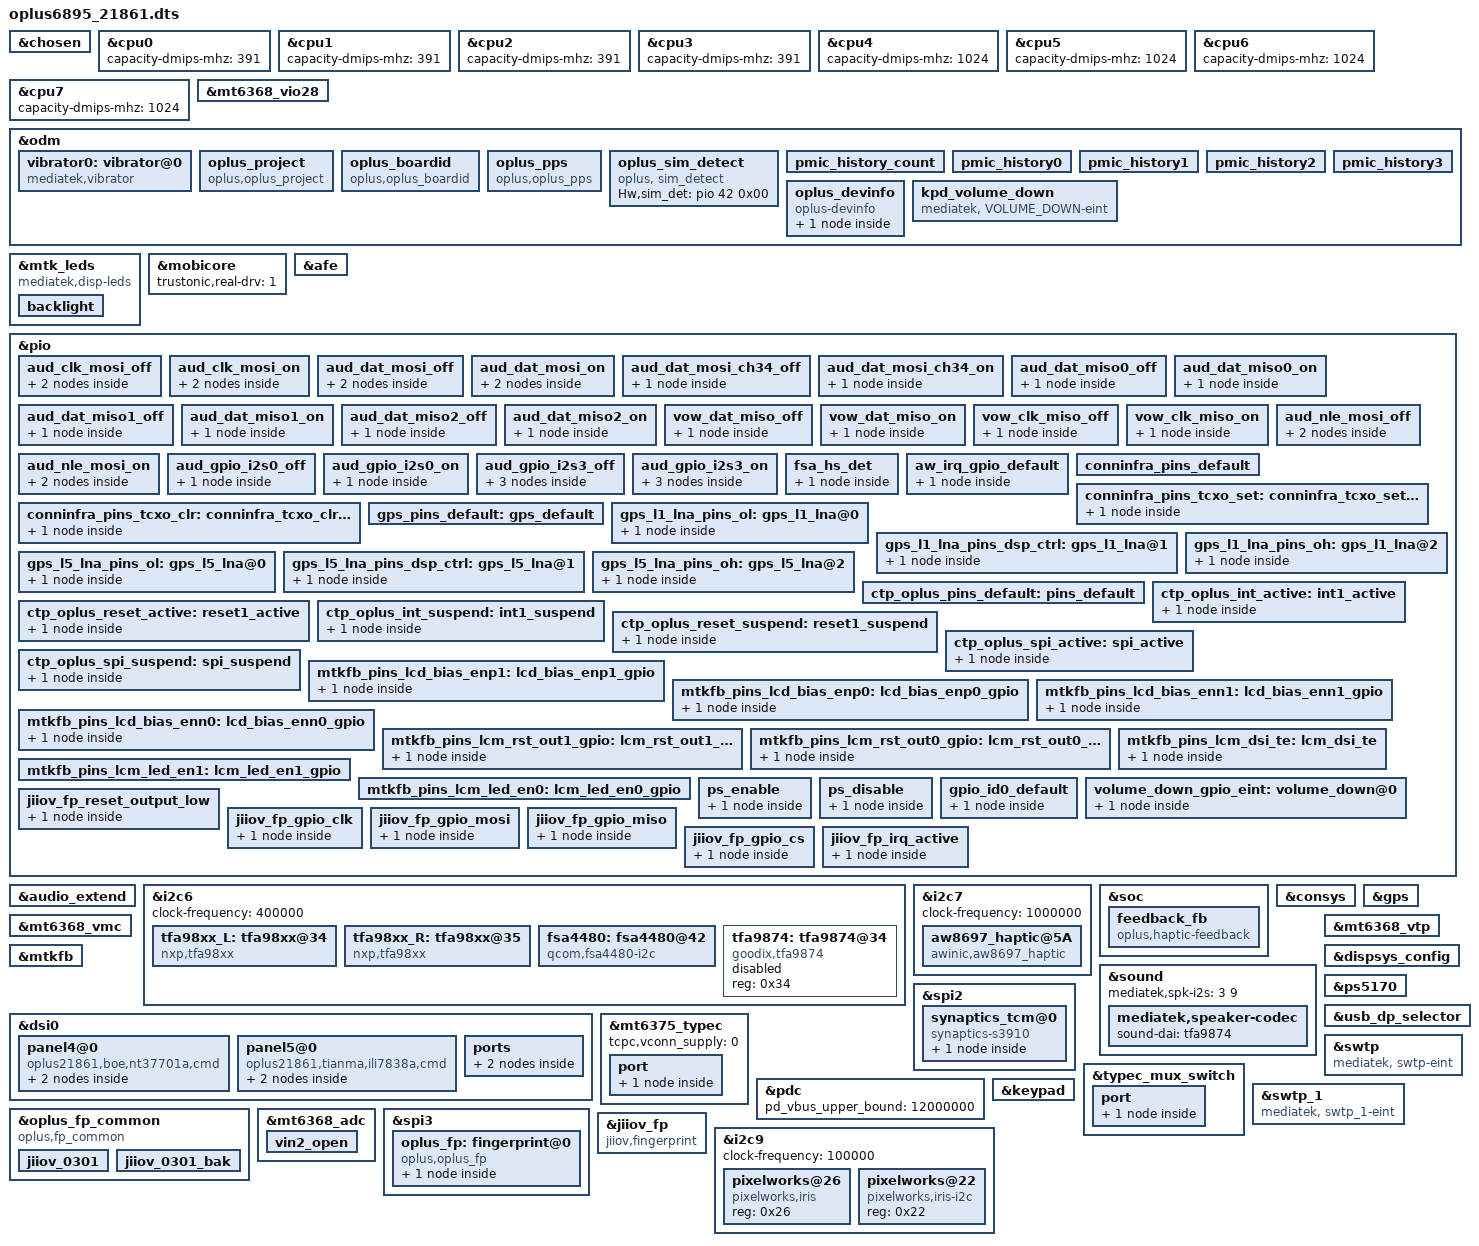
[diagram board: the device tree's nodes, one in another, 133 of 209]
// SPDX-License-Identifier: (GPL-2.0 OR MIT)
/*
 * Copyright (C) 2020 MediaTek Inc.
 * Author: Chun-Hung Wu <chun-hung.wu@mediatek.com>
 */
/dts-v1/;
/plugin/;
#include <dt-bindings/interrupt-controller/arm-gic.h>
#include <dt-bindings/interrupt-controller/irq.h>
#include <dt-bindings/phy/phy.h>
#include <dt-bindings/pinctrl/mt6895-pinfunc.h>
#include "mediatek/oplus_charge_21861.dtsi"
#include <dt-bindings/iio/mt635x-auxadc.h>

//#ifdef OPLUS_FEATURE_NFC_BRINGUP
#include "mediatek/nfc/mt6895_pickle_21861_sn100.dtsi"
//#endif OPLUS_FEATURE_NFC_BRINGUP

//#ifdef OPLUS_FEATURE_SENSOR
#include "mediatek/oplus_sensor_21861.dtsi"
//#endif

&chosen {
	bootargs_ext = "console=tty0 root=/dev/ram \
loglevel=8 \
androidboot.hardware=mt6895 \
initcall_debug=1 ";
};

&cpu0 {
        capacity-dmips-mhz = <391>;
};

&cpu1 {
        capacity-dmips-mhz = <391>;
};

&cpu2 {
        capacity-dmips-mhz = <391>;
};

&cpu3 {
        capacity-dmips-mhz = <391>;
};

&cpu4 {
        capacity-dmips-mhz = <1024>;
};

&cpu5 {
        capacity-dmips-mhz = <1024>;
};

&cpu6 {
        capacity-dmips-mhz = <1024>;
};

&cpu7 {
        capacity-dmips-mhz = <1024>;
};


&mt6368_vio28 {
       regulator-min-microvolt = <3000000>;
       regulator-max-microvolt = <3000000>;
};

&odm {
	vibrator0:vibrator@0 {
		compatible = "mediatek,vibrator";
		vib_timer = <25>;
		vib_limit = <9>;
		vib_vol= <9>;
	};
};

&mtk_leds {
	compatible = "mediatek,disp-leds";
	backlight {
		label = "lcd-backlight";
		led_mode = <4>;
		max-brightness = <10239>;
		max-hw-brightness = <10239>;
		led-bits = <13>;
	};
};

/*Trustonic Mobicore real driver*/
&mobicore {
	trustonic,real-drv=<1>;
};

/* AUDIO GPIO standardization start */
&afe {
	pinctrl-names = "aud_clk_mosi_off",
			"aud_clk_mosi_on",
			"aud_dat_mosi_off",
			"aud_dat_mosi_on",
			"aud_dat_mosi_ch34_off",
			"aud_dat_mosi_ch34_on",
			"aud_dat_miso0_off",
			"aud_dat_miso0_on",
			"aud_dat_miso1_off",
			"aud_dat_miso1_on",
			"aud_dat_miso2_off",
			"aud_dat_miso2_on",
			"vow_dat_miso_off",
			"vow_dat_miso_on",
			"vow_clk_miso_off",
			"vow_clk_miso_on",
			"aud_gpio_i2s3_off",
			"aud_gpio_i2s3_on",
			"aud_gpio_i2s0_off",
			"aud_gpio_i2s0_on";
	pinctrl-0 = <&aud_clk_mosi_off>;
	pinctrl-1 = <&aud_clk_mosi_on>;
	pinctrl-2 = <&aud_dat_mosi_off>;
	pinctrl-3 = <&aud_dat_mosi_on>;
	pinctrl-4 = <&aud_dat_mosi_ch34_off>;
	pinctrl-5 = <&aud_dat_mosi_ch34_on>;
	pinctrl-6 = <&aud_dat_miso0_off>;
	pinctrl-7 = <&aud_dat_miso0_on>;
	pinctrl-8 = <&aud_dat_miso1_off>;
	pinctrl-9 = <&aud_dat_miso1_on>;
	pinctrl-10 = <&aud_dat_miso2_off>;
	pinctrl-11 = <&aud_dat_miso2_on>;
	pinctrl-12 = <&vow_dat_miso_off>;
	pinctrl-13 = <&vow_dat_miso_on>;
	pinctrl-14 = <&vow_clk_miso_off>;
	pinctrl-15 = <&vow_clk_miso_on>;
	pinctrl-16 = <&aud_gpio_i2s3_off>;
	pinctrl-17 = <&aud_gpio_i2s3_on>;
	pinctrl-18 = <&aud_gpio_i2s0_off>;
	pinctrl-19 = <&aud_gpio_i2s0_on>;
};
&pio {
	aud_clk_mosi_off: aud_clk_mosi_off {
		pins_cmd1_dat {
			pinmux = <PINMUX_GPIO202__FUNC_GPIO202>;
			input-enable;
			bias-pull-down;
		};
		pins_cmd2_dat {
			pinmux = <PINMUX_GPIO203__FUNC_GPIO203>;
			input-enable;
			bias-pull-down;
		};
	};
	aud_clk_mosi_on: aud_clk_mosi_on {
		pins_cmd1_dat {
			pinmux = <PINMUX_GPIO202__FUNC_AUD_CLK_MOSI>;
			input-schmitt-enable;
			bias-disable;
		};
		pins_cmd2_dat {
			pinmux = <PINMUX_GPIO203__FUNC_AUD_SYNC_MOSI>;
			input-schmitt-enable;
			bias-disable;
		};
};
	aud_dat_mosi_off: aud_dat_mosi_off {
		pins_cmd1_dat {
			pinmux = <PINMUX_GPIO204__FUNC_GPIO204>;
			input-enable;
			bias-pull-down;
		};
		pins_cmd2_dat {
			pinmux = <PINMUX_GPIO205__FUNC_GPIO205>;
			input-enable;
			bias-pull-down;
		};
};
	aud_dat_mosi_on: aud_dat_mosi_on {
		pins_cmd1_dat {
			pinmux = <PINMUX_GPIO204__FUNC_AUD_DAT_MOSI0>;
			input-schmitt-enable;
			bias-disable;
		};
		pins_cmd2_dat {
			pinmux = <PINMUX_GPIO205__FUNC_AUD_DAT_MOSI1>;
			input-schmitt-enable;
			bias-disable;
		};
};
	aud_dat_mosi_ch34_off: aud_dat_mosi_ch34_off {
		pins_cmd1_dat {
			pinmux = <PINMUX_GPIO206__FUNC_GPIO206>;
			input-enable;
			bias-pull-down;
		};
	};
	aud_dat_mosi_ch34_on: aud_dat_mosi_ch34_on {
		pins_cmd1_dat {
			pinmux = <PINMUX_GPIO206__FUNC_AUD_DAT_MOSI2>;
			input-schmitt-enable;
			bias-disable;
		};
	};
	aud_dat_miso0_off: aud_dat_miso0_off {
		pins_cmd1_dat {
			pinmux = <PINMUX_GPIO209__FUNC_GPIO209>;
			input-enable;
			bias-pull-down;
		};
	};
	aud_dat_miso0_on: aud_dat_miso0_on {
		pins_cmd1_dat {
			pinmux = <PINMUX_GPIO209__FUNC_AUD_DAT_MISO0>;
			input-schmitt-enable;
			bias-disable;
		};
	};
	aud_dat_miso1_off: aud_dat_miso1_off {
		pins_cmd1_dat {
			pinmux = <PINMUX_GPIO210__FUNC_GPIO210>;
			input-enable;
			bias-disable;
		};
	};
	aud_dat_miso1_on: aud_dat_miso1_on {
		pins_cmd1_dat {
			pinmux = <PINMUX_GPIO210__FUNC_AUD_DAT_MISO1>;
			input-schmitt-enable;
			bias-disable;
		};
	};
	aud_dat_miso2_off: aud_dat_miso2_off {
		pins_cmd1_dat {
			pinmux = <PINMUX_GPIO211__FUNC_GPIO211>;
			input-enable;
			bias-pull-down;
		};
	};
	aud_dat_miso2_on: aud_dat_miso2_on {
		pins_cmd1_dat {
			pinmux = <PINMUX_GPIO211__FUNC_AUD_DAT_MISO2>;
			input-schmitt-enable;
			bias-disable;
		};
	};
	vow_dat_miso_off: vow_dat_miso_off {
		pins_cmd1_dat {
			pinmux = <PINMUX_GPIO209__FUNC_GPIO209>;
			input-enable;
			bias-pull-down;
		};
	};
	vow_dat_miso_on: vow_dat_miso_on {
		pins_cmd1_dat {
			pinmux = <PINMUX_GPIO209__FUNC_VOW_DAT_MISO>;
			input-schmitt-enable;
			bias-disable;
		};
	};
	vow_clk_miso_off: vow_clk_miso_off {
		pins_cmd1_dat {
			pinmux = <PINMUX_GPIO210__FUNC_GPIO210>;
			input-enable;
			bias-pull-down;
		};
	};
	vow_clk_miso_on: vow_clk_miso_on {
		pins_cmd1_dat {
			pinmux = <PINMUX_GPIO210__FUNC_VOW_CLK_MISO>;
			input-schmitt-enable;
			bias-disable;
		};
	};
	aud_nle_mosi_off: aud_nle_mosi_off {
		pins_cmd1_dat {
			pinmux = <PINMUX_GPIO207__FUNC_GPIO207>;
			input-enable;
			bias-pull-down;
		};
		pins_cmd2_dat {
			pinmux = <PINMUX_GPIO208__FUNC_GPIO208>;
			input-enable;
			bias-pull-down;
		};
	};
	aud_nle_mosi_on: aud_nle_mosi_on {
		pins_cmd1_dat {
			pinmux = <PINMUX_GPIO207__FUNC_AUD_NLE_MOSI1>;
			input-schmitt-enable;
			bias-disable;
		};
		pins_cmd2_dat {
			pinmux = <PINMUX_GPIO208__FUNC_AUD_NLE_MOSI0>;
			input-schmitt-enable;
			bias-disable;
		};
	};
	aud_gpio_i2s0_off: aud_gpio_i2s0_off {
		pins_cmd1_dat {
			pinmux = <PINMUX_GPIO117__FUNC_GPIO117>;
			input-enable;
			bias-pull-down;
		};
	};
	aud_gpio_i2s0_on: aud_gpio_i2s0_on {
		pins_cmd1_dat {
			pinmux = <PINMUX_GPIO117__FUNC_I2S0_DI>;
			input-schmitt-enable;
			bias-disable;
		};
	};
	aud_gpio_i2s3_off: aud_gpio_i2s3_off {
		pins_cmd1_dat {
			pinmux = <PINMUX_GPIO115__FUNC_GPIO115>;
			input-enable;
			bias-pull-down;
		};
		pins_cmd2_dat {
			pinmux = <PINMUX_GPIO116__FUNC_GPIO116>;
			input-enable;
			bias-pull-down;
		};
		pins_cmd3_dat {
			pinmux = <PINMUX_GPIO118__FUNC_GPIO118>;
			input-enable;
			bias-pull-down;
		};
	};
	aud_gpio_i2s3_on: aud_gpio_i2s3_on {
		pins_cmd1_dat {
			pinmux = <PINMUX_GPIO115__FUNC_I2S3_BCK>;
			input-schmitt-enable;
			bias-disable;
		};
		pins_cmd2_dat {
			pinmux = <PINMUX_GPIO116__FUNC_I2S3_LRCK>;
			input-schmitt-enable;
			bias-disable;
		};
		pins_cmd3_dat {
			pinmux = <PINMUX_GPIO118__FUNC_I2S3_DO>;
			input-schmitt-enable;
			bias-disable;
		};
	};
};
/* AUDIO GPIO standardization end */

//#ifdef OPLUS_ARCH_EXTENDS
&audio_extend {
	//for nxp speaker
	oplus,speaker-vendor = "nxp";
	oplus,speaker-i2s-id = <3>;
	oplus,speaker-i2s-id-in = <0>;
	oplus,speaker-codec-name = "tfa98xx.6-0034","tfa98xx.6-0035";
	oplus,speaker-codec-dai-name = "tfa98xx-aif-6-34","tfa98xx-aif-6-35";
};

&i2c6 {
	clock-frequency = <400000>;

	tfa98xx_L: tfa98xx@34 {
		compatible = "nxp,tfa98xx";
		reg = <0x34>;
		reset-gpio = <&pio 157 0>;
		tfa_min_range = <5000>;
		tfa_max_range = <8000>;
		tfa_channel = <0>;
		status = "okay";
	};

	tfa98xx_R: tfa98xx@35 {
		compatible = "nxp,tfa98xx";
		reg = <0x35>;
		reset-gpio = <&pio 158 0>;
		tfa_min_range = <5000>;
		tfa_max_range = <8000>;
		tfa_channel = <1>;
		status = "okay";
	};
};

&i2c6 {
	fsa4480: fsa4480@42 {
		compatible = "qcom,fsa4480-i2c";
		reg = <0x42>;
		pinctrl-names = "default";
		pinctrl-0 = <&fsa_hs_det>;
		fsa4480,hs-det-gpio = <&pio 53 0>;
	};
};

&i2c7 {
	status = "okay";
	clock-frequency = <1000000>;

	// AWINIC AW8697 Haptic
	aw8697_haptic@5A {
		status = "okay";
		compatible = "awinic,aw8697_haptic";
		reg = <0x5A>;
		reset-gpio = <&pio 24 0x00>;
		irq-gpio = <&pio 11 0x00>;
		qcom,device_id = <815>;

		pinctrl-names = "default";
		pinctrl-0 = <&aw_irq_gpio_default>;
	};
};

&soc {
	feedback_fb: feedback_fb {
		compatible = "oplus,haptic-feedback";
	};
};

&pio {
	fsa_hs_det: fsa_hs_det {
		pins_cmd_dat {
			pinmux = <PINMUX_GPIO53__FUNC_GPIO53>;
			slew-rate = <1>;  /*direction 0:in, 1:out*/
			output-high;
		};
	};

	aw_irq_gpio_default: aw_irq_gpio_default {
		pins_cmd_dat {
			pinmux = <PINMUX_GPIO11__FUNC_GPIO11>;
			input-enable;
			bias-pull-up;
		};
	};
};
//#endif /*OPLUS_ARCH_EXTENDS*/

&i2c6 {
	tfa9874: tfa9874@34 {
		compatible = "goodix,tfa9874";
		#sound-dai-cells = <0>;
		reg = <0x34>;
		status = "disabled";
	};
};

/*
&i2c6 {
	spk: speaker_amp@5c {
		compatible = "richtek,rt5512";
		#sound-dai-cells = <0>;
		reg = <0x5c>;
		status = "okay";
		sound-name-prefix = "Left";
	};
};
*/

/* CONNSYS TCXO GPIO start */
&consys {
	tcxo_support = "false";
	pinctrl-names = "default", "conninfra_tcxo_set", "conninfra_tcxo_clr";
	pinctrl-0 = <&conninfra_pins_default>;
	pinctrl-1 = <&conninfra_pins_tcxo_set>;
	pinctrl-2 = <&conninfra_pins_tcxo_clr>;
	status = "okay";
};

&pio {
	conninfra_pins_default: conninfra_pins_default {
	};
	conninfra_pins_tcxo_set: conninfra_tcxo_set@gpio {
		pins_cmd_dat {
			pinmux = <PINMUX_GPIO108__FUNC_CONN_TCXOENA_REQ>;
		};
	};
	conninfra_pins_tcxo_clr: conninfra_tcxo_clr@gpio {
		pins_cmd_dat {
			pinmux = <PINMUX_GPIO108__FUNC_GPIO108>;
		};
	};
};
/* CONNSYS TCXO GPIO end */

/* GPS GPIO standardization start */
&pio {
	gps_pins_default: gps_default {
	};

	gps_l1_lna_pins_ol: gps_l1_lna@0 {
		pins_cmd_dat {
			pinmux = <PINMUX_GPIO176__FUNC_GPIO176>;
			output-low;
		};
	};
	gps_l1_lna_pins_dsp_ctrl: gps_l1_lna@1 {
		pins_cmd_dat {
			pinmux = <PINMUX_GPIO176__FUNC_GPS_L1_ELNA_EN>;
		};
	};
	gps_l1_lna_pins_oh: gps_l1_lna@2 {
		pins_cmd_dat {
			pinmux = <PINMUX_GPIO176__FUNC_GPIO176>;
			output-high;
		};
	};

	gps_l5_lna_pins_ol: gps_l5_lna@0 {
		pins_cmd_dat {
			pinmux = <PINMUX_GPIO177__FUNC_GPIO177>;
			output-low;
		};
	};
	gps_l5_lna_pins_dsp_ctrl: gps_l5_lna@1 {
		pins_cmd_dat {
			pinmux = <PINMUX_GPIO177__FUNC_GPS_L5_ELNA_EN>;
		};
	};
	gps_l5_lna_pins_oh: gps_l5_lna@2 {
		pins_cmd_dat {
			pinmux = <PINMUX_GPIO177__FUNC_GPIO177>;
			output-high;
		};
	};
};

&gps {
	pinctrl-names = "default",
		"gps_l1_lna_disable",
		"gps_l1_lna_dsp_ctrl",
		"gps_l1_lna_enable",
		"gps_l5_lna_disable",
		"gps_l5_lna_dsp_ctrl",
		"gps_l5_lna_enable";
	pinctrl-0 = <&gps_pins_default>;
	pinctrl-1 = <&gps_l1_lna_pins_ol>;
	pinctrl-2 = <&gps_l1_lna_pins_dsp_ctrl>;
	pinctrl-3 = <&gps_l1_lna_pins_oh>;
	pinctrl-4 = <&gps_l5_lna_pins_ol>;
	pinctrl-5 = <&gps_l5_lna_pins_dsp_ctrl>;
	pinctrl-6 = <&gps_l5_lna_pins_oh>;
	status = "okay";
};
/* GPS GPIO standardization end */

&sound {
	mediatek,spk-i2s = <3 9>;
	mediatek,speaker-codec {
		sound-dai = <&tfa9874>;
	};
};

&spi2 {
	status = "okay";
	#address-cells = <1>;
	#size-cells = <0>;
	synaptics_tcm@0{
		compatible = "synaptics-s3910";
		reg = <0x0>;
		chip-name = "S3910";
		status = "okay";
		spi-max-frequency = <5000000>;
		/* Interrupt && Irq-gpio */
		interrupt-parent = <&pio>;
		interrupts = <135 0x2008>;

		/* Power Config */
		vdd_2v8-supply  = <&mt6368_vtp>;
		vdd_2v8_volt = <3000000>;
		vcc_1v8-supply  = <&mt6368_vmc>;
		vcc_1v8_volt = <1800000>;
		 
		/* Other HW Resource */

		irq-gpio = <&pio 135 0x2008>;
		reset-gpio = <&pio 212 0x1>;
		//cs-gpio = <&pio 110 0x00>;
		//pinctrl-names = "default";
		//pinctrl-0 = <&ts_int_active &ts_reset_active>;

		pinctrl-names = "default",  "oplus_int_active",
		"oplus_reset_active", "oplus_int_suspend",
		"oplus_reset_suspend", "oplus_spi_active",
		"oplus_spi_suspend";
		pinctrl-0 = <&ctp_oplus_pins_default>;
		pinctrl-1 = <&ctp_oplus_int_active>;
		pinctrl-2 = <&ctp_oplus_reset_active>;
		pinctrl-3 = <&ctp_oplus_int_suspend>;
		pinctrl-4 = <&ctp_oplus_reset_suspend>;
		pinctrl-5 = <&ctp_oplus_spi_active>;
		pinctrl-6 = <&ctp_oplus_spi_suspend>;

		touchpanel,max-num-support = <10>;
		touchpanel,tx-rx-num = <16 36>;
		earsense,tx-rx-num = <17 18>;
		touchpanel,panel-coords = <8640 19296>;
		touchpanel,display-coords = <1080 2412>;
		touchpanel,touchmajor-limit = <128 216>;
		touchpanel,elimination-range = <20 200 200>;
		touchpanel,int-mode = <1>; /*0: interrupt and disable, 1:interrupt and not disable*/
		touchpanel,smooth-level = <0 1 2 4 7 9>;
		touchpanel,smooth-level-charging = <0 2 4 7 8 9>;
		touchpanel,sensitive-level = <0 70 55 40 25 10>;
		touchpanel,single-optimized-time = <8>;
		touchpanel,high-frame-rate-time = <60>;

		vid_len = <2>;
		panel_type = <3 7>; /*type:3 BOE type:7 TIANMA*/
		platform_support_project = <21861 21862 21863 21641 21642 >;
		platform_support_project_dir = <21861 21861 21861 21641 21641 >;
		platform_support_project_commandline = "oplus21861_boe_nt37701a_fhd_dsi_cmd_lcm_drv","oplus21861_tianma_ili7838a_fhd_dsi_cmd_lcm_drv";

		prevention,curved_screen_V2;
		prevention,grip_disable_level = <6>;
		prevention,updelay_time_ms = <45>;
		prevention,makeup_cnt_weight = <5 1 2 2 2>;
		prevention,large_corner_range = <960 2400>;
		prevention,large_corner_judge_condition = <850 100 800 7 7>;
		prevention,trx_reject_condition = <8 7 7>;
		prevention,trx_strict_reject_condition = <8 6 6>;
		prevention,large_judge_time_ms = <500 50 30>;
		prevention,large_exit_condition = <8 8 2>;
		prevention,single_channel_width = <160 160>;
		prevention,normal_tap_condition = <10 350>;
		prevention,long_edge_condition = <240 150 180 80>;
		prevention,long_strict_edge_condition = <160 60>;
		prevention,long_fingerhold_condition = <100 6 4 4>;
		prevention,short_edge_condition = <200 90 180 80>;
		prevention,short_strict_edge_condition = <160 60>;
		prevention,large_strict_exit_condition = <6 6>;
		prevention,top_corner_config = <250 750 100>;
		prevention,edge_swipe_config = <150 500>;


		/* SW Support Feature Control */
		sportify_aod_gesture_support;
		black_gesture_support;
		pressure_report_support;
		charger_pump_support;
		game_switch_support;
		smart_gesture_support;
		spi_port_support;
		fw_update_app_support;
	    fingerprint_underscreen_support;
		freq_hop_simulate_support;
		report_flow_unlock_support;
		screenoff_fingerprint_info_support;
		irq_need_dev_resume_ok;
		enable_point_auto_change;
		report_rate_white_list_support;
		kernel_grip_support;
		//grip_no_driver_support;
		health_monitor_support;
		black_gesture_indep_support;
		algorithm_support;
		snr_read_support;
		exception_upload_support;
		/*
		 *Virtual Key Config:
		 *1:touchpanel,button-type: <virtualkey_type  supportted_button-map>
		 *virtualkey_type:
		 *Type 1: using board_properties
		 *Type 2: using same IC (button zone&& touch zone are seprate)
		 *Type 3: using diffrent IC (button zone&& touch zone are seprate)
		 *Type 4: No need of virtual key process
		 *supportted_button-map:select|menu|home|back
		 *
		 *2:touchpanel,button-map
		 *type (X1,Y1)(X2,Y2)(X3,Y3)(Width_X,Hight_Y)--Only when button-type is 0
		 */
		touchpanel,button-type = <4>;
		touchpanel.button-TRx = <0 0>;

		S3910 {
			switch_report_rate;
			report_rate_default = <60>;
			fps_report_rate = <60 2 90 3 120 3>;//1:360Hz 2:125Hz 3:240Hz
			fwupdate_bootloader = <1>;
			report_rate_game_value = <0x01>;
			default_gesture_mask = <8191>;
			normal_config_version = <0>; /* default config version has been changed to 2 in
				                       latest firmware and ic driver, old projects with
				                       old fw-cfg should config 0 in devicetrees */
		};
	};

};

&pio {
	ctp_oplus_pins_default: pins_default {
	};
	ctp_oplus_int_active: int1_active {
		pins_cmd_dat {
			pinmux = <PINMUX_GPIO135__FUNC_GPIO135>;
			bias-disable;
			input-enable;
		};
	};
	ctp_oplus_reset_active: reset1_active {
		pins_cmd_dat {
			pinmux = <PINMUX_GPIO212__FUNC_GPIO212>;
			output-high;
		};
	};
	ctp_oplus_int_suspend: int1_suspend {
		pins_cmd_dat {
			pinmux = <PINMUX_GPIO135__FUNC_GPIO135>;
			output-low;
		};
	};
	ctp_oplus_reset_suspend: reset1_suspend {
		pins_cmd_dat {
			pinmux = <PINMUX_GPIO212__FUNC_GPIO212>;
			output-low;
		};
	};
	ctp_oplus_spi_active: spi_active {
		pins_cmd_dat {
			pinmux = <PINMUX_GPIO109__FUNC_SPI2_A_MI>,
				<PINMUX_GPIO110__FUNC_SPI2_A_CSB>,
				<PINMUX_GPIO111__FUNC_SPI2_A_MO>,
				<PINMUX_GPIO112__FUNC_SPI2_A_CLK>;
			bias-disable;
			drive-strength = <6>;
		};
	};
	ctp_oplus_spi_suspend: spi_suspend {
		pins_cmd_dat {
			pinmux = < PINMUX_GPIO109__FUNC_GPIO109>,
				< PINMUX_GPIO110__FUNC_GPIO110>,
				<PINMUX_GPIO111__FUNC_GPIO111>,
				< PINMUX_GPIO112__FUNC_GPIO112>;
			bias-disable;
			output-low;
			drive-strength = <6>;
		};
	};
};
&mt6368_vmc {
	regulator-min-microvolt = <1800000>;
	regulator-max-microvolt = <1800000>;
	regulator-boot-on;
	//regulator-always-on;
};
&mt6368_vtp{
	regulator-min-microvolt = <3000000>;
	regulator-max-microvolt = <3000000>;
	regulator-boot-on;
	//regulator-always-on;
};

&pio {
	mtkfb_pins_lcd_bias_enp1: lcd_bias_enp1_gpio {
		pins_cmd_dat {
			pinmux = <PINMUX_GPIO39__FUNC_GPIO39>;
			slew-rate = <1>;
			output-high;
		};
	};

	mtkfb_pins_lcd_bias_enp0: lcd_bias_enp0_gpio {
		pins_cmd_dat {
			pinmux = <PINMUX_GPIO39__FUNC_GPIO39>;
			slew-rate = <1>;
			output-low;
		};
	};

	mtkfb_pins_lcd_bias_enn1: lcd_bias_enn1_gpio {
		pins_cmd_dat {
			pinmux = <PINMUX_GPIO39__FUNC_GPIO39>;
			slew-rate = <1>;
			output-high;
		};
	};

	mtkfb_pins_lcd_bias_enn0: lcd_bias_enn0_gpio {
		pins_cmd_dat {
			pinmux = <PINMUX_GPIO39__FUNC_GPIO39>;
			slew-rate = <1>;
			output-low;
		};
	};

	mtkfb_pins_lcm_rst_out1_gpio: lcm_rst_out1_gpio {
		pins_cmd_dat {
			pinmux = <PINMUX_GPIO41__FUNC_GPIO41>;
			slew-rate = <1>;
			output-high;
		};
	};

	mtkfb_pins_lcm_rst_out0_gpio: lcm_rst_out0_gpio {
		pins_cmd_dat {
			pinmux = <PINMUX_GPIO41__FUNC_GPIO41>;
			slew-rate = <1>;
			output-low;
		};
	};
	mtkfb_pins_lcm_dsi_te: lcm_dsi_te {
		pins_cmd_dat {
			pinmux = <PINMUX_GPIO40__FUNC_DSI_TE>;
		};
	};

	mtkfb_pins_lcm_led_en1: lcm_led_en1_gpio {
	};

	mtkfb_pins_lcm_led_en0: lcm_led_en0_gpio {
	};
};

&mtkfb {
	pinctrl-names = "lcd_bias_enp1_gpio", "lcd_bias_enp0_gpio",
		"lcd_bias_enn1_gpio", "lcd_bias_enn0_gpio",
		"lcm_rst_out1_gpio", "lcm_rst_out0_gpio",
		"mode_te_te", "lcm_led_en1_gpio", "lcm_led_en0_gpio";
	pinctrl-0 = <&mtkfb_pins_lcd_bias_enp1>;
	pinctrl-1 = <&mtkfb_pins_lcd_bias_enp0>;
	pinctrl-2 = <&mtkfb_pins_lcd_bias_enn1>;
	pinctrl-3 = <&mtkfb_pins_lcd_bias_enn0>;
	pinctrl-4 = <&mtkfb_pins_lcm_rst_out1_gpio>;
	pinctrl-5 = <&mtkfb_pins_lcm_rst_out0_gpio>;
	pinctrl-6 = <&mtkfb_pins_lcm_dsi_te>;
	pinctrl-7 = <&mtkfb_pins_lcm_led_en1>;
	pinctrl-8 = <&mtkfb_pins_lcm_led_en0>;

	status = "okay";
};
&dispsys_config {
	pinctrl-names =
		"lcm_rst_out1_gpio", "lcm_rst_out0_gpio",
		"mode_te_te";
	pinctrl-0 = <&mtkfb_pins_lcm_rst_out1_gpio>;
	pinctrl-1 = <&mtkfb_pins_lcm_rst_out0_gpio>;
	pinctrl-2 = <&mtkfb_pins_lcm_dsi_te>;
	status = "okay";

	helper-value = <0>, /*MTK_DRM_OPT_STAGE*/
	<1>, /*MTK_DRM_OPT_USE_CMDQ*/
	<1>, /*MTK_DRM_OPT_USE_M4U*/
	<1>, /*MTK_DRM_OPT_MMQOS_SUPPORT*/
	<1>, /*MTK_DRM_OPT_MMDVFS_SUPPORT*/
	<1>, /*MTK_DRM_OPT_SODI_SUPPORT*/
	<1>, /*MTK_DRM_OPT_IDLE_MGR*/
	<0>, /*MTK_DRM_OPT_IDLEMGR_SWTCH_DECOUPLE*/
	<1>, /*MTK_DRM_OPT_IDLEMGR_BY_REPAINT*/
	<0>, /*MTK_DRM_OPT_IDLEMGR_ENTER_ULPS*/
	<0>, /*MTK_DRM_OPT_IDLEMGR_KEEP_LP11*/
	<1>, /*MTK_DRM_OPT_DYNAMIC_RDMA_GOLDEN_SETTING*/
	<1>, /*MTK_DRM_OPT_IDLEMGR_DISABLE_ROUTINE_IRQ*/
	<0>, /*MTK_DRM_OPT_MET_LOG*/
	<1>, /*MTK_DRM_OPT_USE_PQ*/
	<1>, /*MTK_DRM_OPT_ESD_CHECK_RECOVERY*/
	<1>, /*MTK_DRM_OPT_ESD_CHECK_SWITCH*/
	<1>, /*MTK_DRM_OPT_PRESENT_FENCE*/
	<0>, /*MTK_DRM_OPT_RDMA_UNDERFLOW_AEE*/
	<1>, /*MTK_DRM_OPT_DSI_UNDERRUN_AEE*/
	<1>, /*MTK_DRM_OPT_HRT*/
	<1>, /*MTK_DRM_OPT_HRT_MODE*/
	<0>, /*MTK_DRM_OPT_DELAYED_TRIGGER*/
	<1>, /*MTK_DRM_OPT_OVL_EXT_LAYER*/
	<1>, /*MTK_DRM_OPT_AOD*/
	<1>, /*MTK_DRM_OPT_RPO*/
	<0>, /*MTK_DRM_OPT_DUAL_PIPE*/
	<0>, /*MTK_DRM_OPT_DC_BY_HRT*/
	<1>, /*MTK_DRM_OPT_OVL_WCG*/
	<0>, /*MTK_DRM_OPT_OVL_SBCH*/
	<1>, /*MTK_DRM_OPT_COMMIT_NO_WAIT_VBLANK*/
	<0>, /*MTK_DRM_OPT_MET*/
	<0>, /*MTK_DRM_OPT_REG_PARSER_RAW_DUMP*/
	<0>, /*MTK_DRM_OPT_VP_PQ*/
	<0>, /*MTK_DRM_OPT_GAME_PQ*/
	<0>, /*MTK_DRM_OPT_MMPATH*/
	<1>, /*MTK_DRM_OPT_HBM*/
	<0>, /*MTK_DRM_OPT_VDS_PATH_SWITCH*/
	<0>, /*MTK_DRM_OPT_LAYER_REC*/
	<0>, /*MTK_DRM_OPT_CLEAR_LAYER*/
	<1>, /*MTK_DRM_OPT_LFR*/
	<0>, /*MTK_DRM_OPT_SF_PF*/
	<0>, /*MTK_DRM_OPT_DYN_MIPI_CHANGE*/
	<1>, /*MTK_DRM_OPT_PRIM_DUAL_PIPE*/
	<1>, /*MTK_DRM_OPT_MSYNC2_0*/
        <1>, /*MTK_DRM_OPT_MML_PRIMARY*/
	<0>, /*MTK_DRM_OPT_DUAL_TE*/
	<1>; /*MTK_DRM_OPT_RES_SWITCH*/
};


&dsi0 {
	status = "okay";
	#address-cells = <1>;
	#size-cells = <0>;
        panel4@0 {
                compatible = "oplus21861,boe,nt37701a,cmd";
                reg = <0>;
                vddr-enable-gpios = <&pio 120 0>;
		vddr-aod-en-gpios = <&pio 22 0>;
                pw-1p8-gpios = <&pio 213 0>;
                pw-reset-gpios = <&pio 193 0>;
                reset-gpios = <&pio 41 0>;
                //vmcldo-supply = <&mt6368_vmc>;
                vufsldo-supply = <&mt6363_vufs18>;
		vmchldo-supply = <&mt6368_vmch>;
/* #if defined(CONFIG_PXLW_IRIS) */
                irisreset-gpios = <&pio 193 0>;
                irisabyp-gpios = <&pio 188 0>;
                irisready-gpios = <&pio 189 0>;
/* #endif */
                pinctrl-names = "default";
                port {
                        panel_in4: endpoint {
                                remote-endpoint = <&dsi_out>;
                        };
                };
        };
        panel5@0 {
                compatible = "oplus21861,tianma,ili7838a,cmd";
                reg = <1>;
                vddr-enable-gpios = <&pio 120 0>;
		vddr-aod-en-gpios = <&pio 22 0>;
                pw-1p8-gpios = <&pio 213 0>;
                pw-reset-gpios = <&pio 193 0>;
                reset-gpios = <&pio 41 0>;
                //vmcldo-supply = <&mt6368_vmc>;
                vufsldo-supply = <&mt6363_vufs18>;
		vmchldo-supply = <&mt6368_vmch>;
/* #if defined(CONFIG_PXLW_IRIS) */
                irisreset-gpios = <&pio 193 0>;
                irisabyp-gpios = <&pio 188 0>;
                irisready-gpios = <&pio 189 0>;
/* #endif */
                pinctrl-names = "default";
                port {
                        panel_in5: endpoint {
                                remote-endpoint = <&dsi_out>;
                        };
                };
        };
	ports {
		port {
			dsi_out: endpoint {
				remote-endpoint = <&panel_in4>;
			};
		};
	};
};

&odm {
/*OPLUS_BUG_STABILITY oplus project start */
	oplus_project:oplus_project {
		compatible = "oplus,oplus_project";
	};
/*endif*/

	oplus_boardid:oplus_boardid {
		compatible = "oplus,oplus_boardid";
		oplus_boardid,dtsino="21861";//only one u32
		oplus_boardid,pcbmask="0xffff";//all mask 0xffff
	};
};
/*#ifdef OPLUS_FEATURE_CHG_BASIC*/
&odm {
	oplus_pps:oplus_pps {
		compatible = "oplus,oplus_pps";
	};
};
/*endif*/

&odm {
//#ifdef OPLUS_FEATURE_TP_BASIC
    oplus_sim_detect {
        compatible = "oplus, sim_detect";
        Hw,sim_det = <&pio 42 0x00>;
    };
//#endif /* OPLUS_FEATURE_TP_BASIC */

	pmic_history_count:pmic_history_count {
	};
	pmic_history0:pmic_history0 {
	};
	pmic_history1:pmic_history1 {
	};
	pmic_history2:pmic_history2 {
	};
	pmic_history3:pmic_history3 {
	};
};

/*&gpio_keys {
        volumedown {
            label = "Volume_Down";
            linux,code = <114>;
            gpios = <&pio 127 1>;
            wakeup-source;
            debounce-interval = <5>;
        };
};
*/
/* usb typec mux start */
&pio {

	ps_enable: ps_enable {
		pins_cmd_dat {
//			pinmux = <PINMUX_GPIO158__FUNC_GPIO158>;
			output-high;
		};
	};

	ps_disable: ps_disable {
		pins_cmd_dat {
//			pinmux = <PINMUX_GPIO158__FUNC_GPIO158>;
			output-low;
		};
	};

};

&mt6375_typec {
	tcpc,vconn_supply  = <0>;
	port {
		tcpc_typec_usb: endpoint@0 {
			remote-endpoint = <&ssusb_mux>;
		};
	};
};

&typec_mux_switch {
	orientation-switch;
	mode-switch;
	accessory;
	port {
		ssusb_mux: endpoint@0 {
			remote-endpoint = <&tcpc_typec_usb>;
		};
	};
};

&ps5170 {
	pinctrl-names = "enable", "disable";
	pinctrl-0 = <&ps_enable>;
	pinctrl-1 = <&ps_disable>;
	status = "okay";
};

&usb_dp_selector {
	status = "okay";
};
/* usb typec mux end */

&pdc {
	pd_vbus_upper_bound = <12000000>;
};

//#ifdef OPLUS_FEATURE_SWTP
&swtp {
    compatible = "mediatek, swtp-eint";
};
&swtp_1 {
    compatible = "mediatek, swtp_1-eint";
};
//#endif  /* OPLUS_FEATURE_SWTP */

//ifdef OPLUS_FEATURE_FINGERPRINT
&oplus_fp_common {
	compatible = "oplus,fp_common";
	oplus,fp_gpio_num = <1>;
	oplus,fp_gpio = <163>;
	oplus,fp_gpio_0 = <&pio 163 0x0>;
	pinctrl-names = "default";
	pinctrl-0 = <&gpio_id0_default>;
	jiiov_0301 {
		oplus,fp-id = <0>; // fp id mapping table
		vendor-chip = <24>; // please refer to the struct fp_vendor_t in oplus_fp_commmon.n
		eng-menu = "-1,-1"; // represents SNR, inclination test item in engineer menu, and 0/1 means off/on
		chip-name = "JIIOV_0301";  // /proc/fp_id, will be displayed in engineer menu
	};
	jiiov_0301_bak {
		oplus,fp-id = <1>; // fp id mapping table
		vendor-chip = <24>; // please refer to the struct fp_vendor_t in oplus_fp_commmon.n
		eng-menu = "-1,-1"; // represents SNR, inclination test item in engineer menu, and 0/1 means off/on
		chip-name = "JIIOV_0301";  // /proc/fp_id, will be displayed in engineer menu
	};
};
&pio{
	gpio_id0_default: gpio_id0_default {
		pins_cmd_dat {
			pinmux = <PINMUX_GPIO163__FUNC_GPIO163>;
			slew-rate = <0>;
			bias-pull-up = <00>;
			input-enable;
		};
	};
};

//#endif /*OPLUS_FEATURE_FINGERPRINT*/

//#ifdef OPLUS_FEATURE_TP_BASIC
&mt6368_adc {
                 vin2_open {
                                channel = <AUXADC_VIN2>;
                                pures = <ADC_PURES_OPEN>;
                           };
            };

&odm {
        oplus_devinfo:oplus_devinfo {
                compatible = "oplus-devinfo";
                io-channels = <&mt6368_adc (ADC_PURES_OPEN_MASK | AUXADC_VIN2)>;
                io-channel-names = "vph_pwr_voltage_sub";
                main-sub {
                        compatible = "hw-match, main-sub";
                        use_pmic_adc;
                        adc_ranges = <0 80
                                      81 180
                                      181 300
                                      301 420
                                      421 550
                                      551 650
                                      651 760
                                      761 850
                                      851 950
                                      951 1080
                                      1081 1180
                                      1181 1300>;
                        aboard-patterns = <0 0 0 1 1 1 1 1 1 0 0 0>;        /*0[high-resistance] 1[pull-down] 2[pull-up]*/
                        /*main board*/
                        match-projects = <21641 21642 21649 0x216BE 0x216BF 0x216C6 0x216C7 0x216E5 0x216E6 21861 21862 21863>;
                };
        };

	kpd_volume_down:kpd_volume_down {
                compatible = "mediatek, VOLUME_DOWN-eint";
                interrupt-parent = <&pio>;
                interrupts = <127 IRQ_TYPE_EDGE_FALLING 127 0>;
                debounce = <32000>;
                status = "okay";
        };

//#endif OPLUS_FEATURE_TP_BASIC
};

&keypad {
        keypad,volume-down = <&pio 127 0x00>;
        pinctrl-names = "volume_down_as_int";
        pinctrl-0 = <&volume_down_gpio_eint>;
        status = "okay";
};

&pio {
        volume_down_gpio_eint:volume_down@0{
                pins_cmd_dat {
                        pinmux = <PINMUX_GPIO127__FUNC_GPIO127>;
                        slew-rate = <0>;  /*direction 0:in, 1:out*/
                        input-enable;
                };
        };
};


&spi3 {
#address-cells = <1>;
#size-cells = <0>;
status = "okay";
oplus_fp: fingerprint@0 {
		compatible = "oplus,oplus_fp";
		reg = <0>;
		spi-max-frequency = <50000000>;
		spi-id = <3>;
		spi-irq = <22>;
		spi-reg = <11013000>;
		dvdd-supply = <&mt6368_vfp>;
		dvdd-config = <3300000 3300000 150000>;
		power-num = <1>;
		status = "okay";
		power_source_1 {
			power-mode = <1>;
			power-name = "dvdd";
			power-config = "dvdd-config";
			delay-time = <0>;
		};
	};
};

&jiiov_fp {
	compatible = "jiiov,fingerprint";
	anc,gpio_irq = <&pio 136 0x00>;
	anc,gpio_rst = <&pio 216 0x00>;
	ldo-supply = <&mt6368_vfp>;
	pinctrl-names = "anc_reset_reset", "anc_reset_active", "anc_irq_active";
	pinctrl-0 = <&jiiov_fp_reset_output_low>;
	pinctrl-1 = <&jiiov_fp_gpio_clk>, <&jiiov_fp_gpio_mosi>, <&jiiov_fp_gpio_miso>, <&jiiov_fp_gpio_cs>, <&jiiov_fp_irq_active>;
	pinctrl-2 = <&jiiov_fp_irq_active>;
	status = "okay";
};

&pio{
jiiov_fp_reset_output_low: jiiov_fp_reset_output_low {
				pins_cmd_dat {
					pinmux = <PINMUX_GPIO216__FUNC_GPIO216>;
					slew-rate = <1>;
					output-low;
				};
			};
jiiov_fp_gpio_clk: jiiov_fp_gpio_clk {
				pins_cmd_dat {
					pinmux = <PINMUX_GPIO217__FUNC_SPI3_A_CLK>;
					drive-strength = <2>;
				};
			};
jiiov_fp_gpio_mosi: jiiov_fp_gpio_mosi {
				pins_cmd_dat {
					pinmux = <PINMUX_GPIO220__FUNC_SPI3_A_MO>;
					drive-strength = <2>;
				};
			};
jiiov_fp_gpio_miso: jiiov_fp_gpio_miso {
				pins_cmd_dat {
					pinmux = <PINMUX_GPIO219__FUNC_SPI3_A_MI>;
					drive-strength = <3>;
				};
			};
jiiov_fp_gpio_cs: jiiov_fp_gpio_cs {
				pins_cmd_dat {
					pinmux = <PINMUX_GPIO218__FUNC_SPI3_A_CSB>;
					drive-strength = <2>;
				};
			};
jiiov_fp_irq_active: jiiov_fp_irq_active {
				pins_cmd_dat {
					pinmux = <PINMUX_GPIO136__FUNC_GPIO136>;
					slew-rate = <0>;
					input-enable;
					bias-pull-down;
				};
			};
};
//#endif /*OPLUS_FEATURE_FINGERPRINT*/

/* #if defined(CONFIG_PXLW_IRIS) */
&i2c9 {
	status = "okay";
	clock-frequency = <100000>;
	#address-cells = <1>;
	#size-cells = <0>;
	pixelworks@26 { /*slave driver and slave address*/
		status = "okay";
		compatible = "pixelworks,iris";  /*Manufacture, model*/
		reg = <0x26>; /*slave address*/
	};

	pixelworks@22 { /*slave driver and slave address*/
		status = "okay";
		compatible = "pixelworks,iris-i2c";  /*Manufacture, model*/
		reg = <0x22>; /*slave address*/
	};
};

#include "mediatek/iris/pxlw-iris-boe-nt37701a-cfg.dtsi"
/* #endif */

//#include "mediatek/cust_mt6895_camera_v4l2.dtsi"
#include <k6895v1_64/cust.dtsi>
#include "mediatek/cust_mt6895_pickle_camera_v4l2.dtsi"
#include "mediatek/cust_mt6895_pickle_thermal.dtsi"
/*End of this file, DO NOT ADD ANYTHING HERE*/
